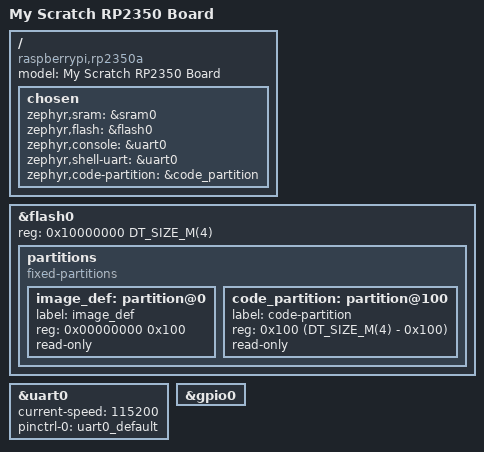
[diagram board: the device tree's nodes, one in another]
/dts-v1/;

#include <raspberrypi/rpi_pico/rp2350a.dtsi>
#include <raspberrypi/rpi_pico/m33.dtsi>
#include "my_scratch-pinctrl.dtsi"

/ {
	model = "My Scratch RP2350 Board";
	compatible = "raspberrypi,rp2350a";

	chosen {
		zephyr,sram = &sram0;
		zephyr,flash = &flash0;
		zephyr,console = &uart0;
		zephyr,shell-uart = &uart0;
		zephyr,code-partition = &code_partition;
	};
};

&flash0 {
	reg = <0x10000000 DT_SIZE_M(4)>;

	partitions {
		compatible = "fixed-partitions";
		#address-cells = <1>;
		#size-cells = <1>;

		image_def: partition@0 {
			label = "image_def";
			reg = <0x00000000 0x100>;
			read-only;
		};

		code_partition: partition@100 {
			label = "code-partition";
			reg = <0x100 (DT_SIZE_M(4) - 0x100)>;
			read-only;
		};
	};
};

&uart0 {
	status = "okay";
	current-speed = <115200>;
	pinctrl-0 = <&uart0_default>;
	pinctrl-names = "default";
};

&gpio0 {
	status = "okay";
};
